# AC78xx register map
Vendor: AutoChips; Series: AC78xx; File version: 1.0
CPU: CM3 r2p1, little endian, MPU, no FPU, 3 interrupt priority bits
Registers are 32-bit, read-write, no defined reset value unless marked. A register's access mark holds for its fields unless they carry their own. Offsets are from the block's base; [hi:lo] are bit positions.

## TIMER — Timer Setting
Base 0x40011000
0x00 MCR reset 0x6 — Timer Module Control Regitser
  [1] MDIS — Timers Module Disable Register
    0=Timers are enabled; 1=Timers are disabled

## TIMER0 — Timer0 Function
Base 0x40011100; register names take the prefix TIMER0_
0x00 INITVAL reset 0x0 — Timer Init Load Value Register
  [31:0] LDVAL — Timer Init Load Value
0x04 CVAL ro reset 0x0 — Timer Current Count Value Register
  [31:0] CNT — Current Timer Count Value
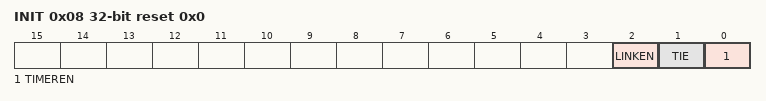
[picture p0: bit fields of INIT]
0x08 INIT reset 0x0 — Timer Initialize Control Register
  [2] LINKEN — Timer Link Mode
    0=Timer is not linked,Timer is seperated; 1=Timer is Linked to previous timer
  [1] TIE — Timer Interrupt Enable
    0=Interrupt requests from Timer n are disabled; 1=Interrupt will be requested whenever TIF is set
  [0] TIMEREN — Timer Enable
    0=Timer is disabled; 1=Timer is enabled
0x0C TF reset 0x0 — Timer Flag Register
  [0] TIF — Timer Interrupt Flag
    0=Timeout has not yet occurred; 1=Timeout has occurred

## TIMER1 — Timer1 Function
Base 0x40011110; register names take the prefix TIMER1_
Registers as TIMER0.

## TIMER2 — Timer2 Function
Base 0x40011120; register names take the prefix TIMER2_
Registers as TIMER0.

## TIMER3 — Timer3 Function
Base 0x40011130; register names take the prefix TIMER3_
Registers as TIMER0.

## TIMER4 — Timer4 Function
Base 0x40011140; register names take the prefix TIMER4_
Registers as TIMER0.

## TIMER5 — Timer5 Function
Base 0x40011150; register names take the prefix TIMER5_
Registers as TIMER0.

## TIMER6 — Timer6 Function
Base 0x40011160; register names take the prefix TIMER6_
Registers as TIMER0.

## TIMER7 — Timer7 Function
Base 0x40011170; register names take the prefix TIMER7_
Registers as TIMER0.

## RTC — Real-time counter
Base 0x40008400; register names take the prefix RTC_
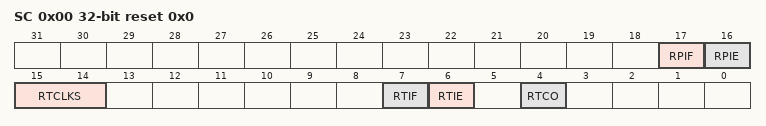
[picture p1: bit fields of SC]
0x00 SC reset 0x0 — RTC Status and Control Register
  [17] RPIF — Real-Time Prescaler Interrupt Flag
  [16] RPIE — Real-Time Prescaler Interrupt Enable
  [15:14] RTCLKS — Real-Time Clock Source Select
    0=External clock source; 1=Real-Time clock source is 1KHz(LPOCLK); 2=Internal reference clock(ICSIRCLK); 3=Bus Clock
  [7] RTIF — Real-Time Interrupt Flag
  [6] RTIE — Real-Time Interrupt Enable
  [4] RTCO — Real-Time Counter Output
0x04 MOD reset 0x0 — RTC Modulo Value
  [31:0] MOD — Modulo
0x08 CNT reset 0x0 — RTC Count Value
  [31:0] CNT — Count Value
0x0C RTCPS reset 0x0 — RTC Real Time Prescaler Register
  [19:0] RTCPS — RTC Prescale Value
0x10 PSCNT reset 0x0 — RTC Prescaler Counter Register
  [19:0] PSCNT

## WDOG — Watchdog timer
Base 0x4000B000; register names take the prefix WDOG_
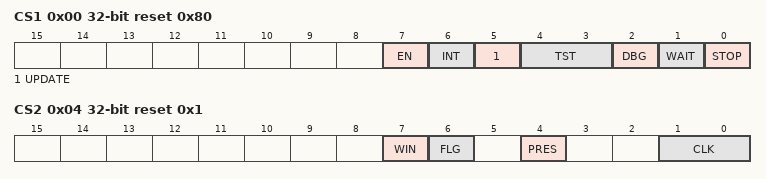
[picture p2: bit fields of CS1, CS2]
0x00 CS1 reset 0x80 — Watchdog Control and Status Register 1
  [7] EN — Watchdog Enable
    0=Watchdog disabled; 1=Watchdog enabled
  [6] INT — Watchdog Interrupt
    0=Watchdog interrupts are disabled. Watchdog resets are not delayed.; 1=Watchdog interrupts are enabled. Watchdog resets are delayed by 128 bus clocks.
  [5] UPDATE — Allow updates
    0=Updates not allowed. After the initial configuration, the watchdog cannot be later modified without forcing a reset.; 1=Updates allowed. Software can modify the watchdog configuration registers within 128 bus clocks after performing the unlock write sequence.
  [4:3] TST — Watchdog Test
    0=Watchdog test mode disabled; 1=Watchdog user mode enabled. (Watchdog test mode disabled.) After testing the watchdog, software should use this setting to indicate that the watchdog is functioning normally in user mode.; 2=Watchdog test mode enabled, only the low byte is used. WDOG_CNTL is compared with WDOG_TOVALL.; 3=Watchdog test mode enabled, only the high byte is used. WDOG_CNTH is compared with WDOG_TOVALH.
  [2] DBG — Debug Enable
    0=Watchdog disabled in chip debug mode; 1=Watchdog enabled in chip debug mode
  [1] WAIT — Wait Enable
    0=Watchdog disabled in chip wait mode; 1=Watchdog enabled in chip wait mode
  [0] STOP — Stop Enable
    0=Watchdog disabled in chip stop mode; 1=Watchdog enabled in chip stop mode
0x04 CS2 reset 0x1 — Watchdog Control and Status Register 2
  [7] WIN — Watchdog Window
    0=Window mode disabled; 1=Window mode enabled
  [6] FLG — Watchdog Interrupt Flag
    0=No interrupt occurred; 1=An interrupt occurred
  [4] PRES — Watchdog Prescalar
    0=256 prescalar disabled; 1=256 prescalar enabled
  [1:0] CLK — Watchdog Clock
    0=Bus clock; 1=1 kHz internal low-power oscillator (LPOCLK); 2=32 kHz internal oscillator (ICSIRCLK); 3=External clock source
0x08 CNT reset 0x0 — Watchdog Counter Value
0x0C TOVAL reset 0x0 — Watchdog Timeout Value Register
  [31:0] TOVAL — WatchDog Timeout Value
0x10 WIN reset 0x0 — Watchdog Window Register
  [31:0] WIN — Watchdog Window
